AUTOSAR XML (schema 4-2-2)
standard types defined: uint8, uint16
package /ASW_COM_Package
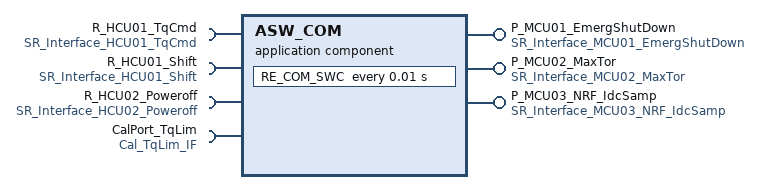
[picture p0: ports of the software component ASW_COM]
  application sw component type ASW_COM
    provide port P_MCU01_EmergShutDown: nonqueued-sender-com-spec{data-element=DE_EmergShutDown, init-value=0}, provided-interface=SR_Interface_MCU01_EmergShutDown
    provide port P_MCU02_MaxTor: nonqueued-sender-com-spec{data-element=DE_MaxTor, init-value=0}, provided-interface=SR_Interface_MCU02_MaxTor
    provide port P_MCU03_NRF_IdcSamp: nonqueued-sender-com-spec{data-element=DE_IdcSamp, init-value=0}, provided-interface=SR_Interface_MCU03_NRF_IdcSamp
    4 x require port:
      R_HCU01_TqCmd: nonqueued-receiver-com-spec{data-element=DE_TqCmd, filter=data-filter-type=ALWAYS, init-value=0}, required-interface=SR_Interface_HCU01_TqCmd
      R_HCU01_Shift: nonqueued-receiver-com-spec{data-element=DE_Shift, filter=data-filter-type=ALWAYS, init-value=0}, required-interface=SR_Interface_HCU01_Shift
      R_HCU02_Poweroff: nonqueued-receiver-com-spec{data-element=DE_Poweroff, alive-timeout=0.3, filter=data-filter-type=ALWAYS, init-value=0}, required-interface=SR_Interface_HCU02_Poweroff
      CalPort_TqLim: nonqueued-receiver-com-spec{data-element=DE_TqLim, alive-timeout=0.3, filter=data-filter-type=ALWAYS, init-value=400}, required-interface=Cal_TqLim_IF
    behavior IB_ASW_COM
      timing event TE_RE_COM_SWC_10ms: start-on-event=RE_COM_SWC, period=0.01
      runnable RE_COM_SWC
        data-receive-point-by-values:
          4 x access:
            REC_HCU01_TqCmd_DE_TqCmd: accessed-variable=R_HCU01_TqCmd.DE_TqCmd
            REC_HCU01_Shift_DE_Shift: accessed-variable=R_HCU01_Shift.DE_Shift
            REC_HCU02_Poweroff_DE_Poweroff: accessed-variable=R_HCU02_Poweroff.DE_Poweroff
            REC_CalPort_TqLim_DE_TqLim: accessed-variable=CalPort_TqLim.DE_TqLim
        data-send-points:
          access SEND_MCU01_EmergShutDown_DE_EmergShutDown: accessed-variable=P_MCU01_EmergShutDown.DE_EmergShutDown
          access SEND_MCU02_MaxTor_DE_MaxTor: accessed-variable=P_MCU02_MaxTor.DE_MaxTor
          access SEND_MCU03_NRF_IdcSamp_DE_IdcSamp: accessed-variable=P_MCU03_NRF_IdcSamp.DE_IdcSamp
package /COM_Interface
  7 x sender receiver interface:
    SR_Interface_MCU01_EmergShutDown
      data DE_EmergShutDown: type=dt_boolean
    SR_Interface_MCU02_MaxTor
      data DE_MaxTor: type=dt_torque
    SR_Interface_MCU03_NRF_IdcSamp
      data DE_IdcSamp: type=dt_current
    SR_Interface_HCU01_TqCmd
      data DE_TqCmd: type=dt_torque
    SR_Interface_HCU01_Shift
      data DE_Shift: type=dt_shift
    SR_Interface_HCU02_Poweroff
      data DE_Poweroff: type=dt_boolean
    Cal_TqLim_IF
      data DE_TqLim: type=dt_torque
package /DataTypes
  4 x impl type, all with category=VALUE:
    dt_boolean: base-type=uint8
    dt_torque: base-type=uint16
    dt_current: base-type=uint16
    dt_shift: base-type=uint8
